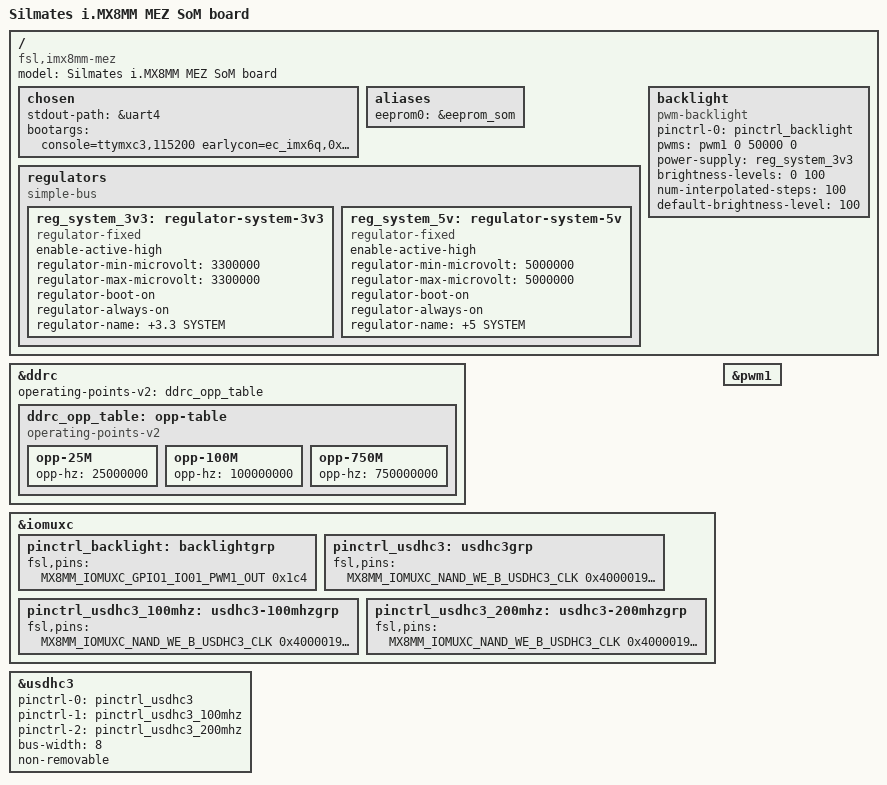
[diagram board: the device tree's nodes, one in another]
// SPDX-License-Identifier: (GPL-2.0+ OR MIT)
/*
 * Copyright 2019-2020 NXP
 */

/dts-v1/;

#include <dt-bindings/usb/pd.h>
#include "imx8mm-mez.dtsi"

/ {
	model = "Silmates i.MX8MM MEZ SoM board";
	compatible = "fsl,imx8mm-mez", "fsl,imx8mm";

	chosen {
		stdout-path = &uart4;
		bootargs = "console=ttymxc3,115200 earlycon=ec_imx6q,0x30a60000,115200";
	};

	aliases {
		eeprom0 = &eeprom_som;
	};

	regulators {
		compatible = "simple-bus";
		#address-cells = <1>;
		#size-cells = <0>;

		reg_system_3v3: regulator-system-3v3 {
			compatible = "regulator-fixed";
			enable-active-high;
			regulator-min-microvolt = <3300000>;
			regulator-max-microvolt = <3300000>;
			regulator-boot-on;
			regulator-always-on;
			regulator-name = "+3.3 SYSTEM";
		};

		reg_system_5v: regulator-system-5v {
			compatible = "regulator-fixed";
			enable-active-high;
			regulator-min-microvolt = <5000000>;
			regulator-max-microvolt = <5000000>;
			regulator-boot-on;
			regulator-always-on;
			regulator-name = "+5 SYSTEM";
		};
	};
	
	backlight: backlight {
		pinctrl-names = "default";
		pinctrl-0 = <&pinctrl_backlight>;
		compatible = "pwm-backlight";
		pwms = <&pwm1 0 50000 0>; /* period = 5000000 ns => f = 200 Hz */
		power-supply = <&reg_system_3v3>;
		brightness-levels = <0 100>;
		num-interpolated-steps = <100>;
		default-brightness-level = <100>;
		status = "okay";
	};
};

&ddrc {
	operating-points-v2 = <&ddrc_opp_table>;

	ddrc_opp_table: opp-table {
		compatible = "operating-points-v2";

		opp-25M {
			opp-hz = /bits/ 64 <25000000>;
		};

		opp-100M {
			opp-hz = /bits/ 64 <100000000>;
		};

		opp-750M {
			opp-hz = /bits/ 64 <750000000>;
		};
	};
};

&iomuxc {

	/* display backlight */
	pinctrl_backlight: backlightgrp {
		fsl,pins = <
			MX8MM_IOMUXC_GPIO1_IO01_PWM1_OUT		0x1c4
		>;
	};


	
// 	pinctrl_flexspi: flexspigrp {
// 		fsl,pins = <
// 			MX8MM_IOMUXC_NAND_ALE_QSPI_A_SCLK               0x1c2
// 			MX8MM_IOMUXC_NAND_CE0_B_QSPI_A_SS0_B            0x82
// 			MX8MM_IOMUXC_NAND_DATA00_QSPI_A_DATA0           0x82
// 			MX8MM_IOMUXC_NAND_DATA01_QSPI_A_DATA1           0x82
// 			MX8MM_IOMUXC_NAND_DATA02_QSPI_A_DATA2           0x82
// 			MX8MM_IOMUXC_NAND_DATA03_QSPI_A_DATA3           0x82
// 		>;
// 	};

	/* eMMC */
	pinctrl_usdhc3: usdhc3grp {
		fsl,pins = <
			MX8MM_IOMUXC_NAND_WE_B_USDHC3_CLK               0x40000190
			MX8MM_IOMUXC_NAND_WP_B_USDHC3_CMD               0x1d0
			MX8MM_IOMUXC_NAND_DATA04_USDHC3_DATA0           0x1d0
			MX8MM_IOMUXC_NAND_DATA05_USDHC3_DATA1           0x1d0
			MX8MM_IOMUXC_NAND_DATA06_USDHC3_DATA2           0x1d0
			MX8MM_IOMUXC_NAND_DATA06_USDHC3_DATA2           0x1d0
			MX8MM_IOMUXC_NAND_DATA07_USDHC3_DATA3           0x1d0
			MX8MM_IOMUXC_NAND_RE_B_USDHC3_DATA4             0x1d0
			MX8MM_IOMUXC_NAND_CE2_B_USDHC3_DATA5            0x1d0
			MX8MM_IOMUXC_NAND_CE3_B_USDHC3_DATA6            0x1d0
			MX8MM_IOMUXC_NAND_CLE_USDHC3_DATA7              0x1d0
			MX8MM_IOMUXC_NAND_CE1_B_USDHC3_STROBE           0x190
		>;
	};

	/* eMMC 100 MHz */
	pinctrl_usdhc3_100mhz: usdhc3-100mhzgrp {
		fsl,pins = <
			MX8MM_IOMUXC_NAND_WE_B_USDHC3_CLK               0x40000194
			MX8MM_IOMUXC_NAND_WP_B_USDHC3_CMD               0x1d4
			MX8MM_IOMUXC_NAND_DATA04_USDHC3_DATA0           0x1d4
			MX8MM_IOMUXC_NAND_DATA05_USDHC3_DATA1           0x1d4
			MX8MM_IOMUXC_NAND_DATA06_USDHC3_DATA2           0x1d4
			MX8MM_IOMUXC_NAND_DATA07_USDHC3_DATA3           0x1d4
			MX8MM_IOMUXC_NAND_RE_B_USDHC3_DATA4             0x1d4
			MX8MM_IOMUXC_NAND_CE2_B_USDHC3_DATA5            0x1d4
			MX8MM_IOMUXC_NAND_CE3_B_USDHC3_DATA6            0x1d4
			MX8MM_IOMUXC_NAND_CLE_USDHC3_DATA7              0x1d4
			MX8MM_IOMUXC_NAND_CE1_B_USDHC3_STROBE           0x194
		>;
	};

	/* eMMC 200 MHz */
	pinctrl_usdhc3_200mhz: usdhc3-200mhzgrp {
		fsl,pins = <
			MX8MM_IOMUXC_NAND_WE_B_USDHC3_CLK               0x40000196
			MX8MM_IOMUXC_NAND_WP_B_USDHC3_CMD               0x1d6
			MX8MM_IOMUXC_NAND_DATA04_USDHC3_DATA0           0x1d6
			MX8MM_IOMUXC_NAND_DATA05_USDHC3_DATA1           0x1d6
			MX8MM_IOMUXC_NAND_DATA06_USDHC3_DATA2           0x1d6
			MX8MM_IOMUXC_NAND_DATA07_USDHC3_DATA3           0x1d6
			MX8MM_IOMUXC_NAND_RE_B_USDHC3_DATA4             0x1d6
			MX8MM_IOMUXC_NAND_CE2_B_USDHC3_DATA5            0x1d6
			MX8MM_IOMUXC_NAND_CE3_B_USDHC3_DATA6            0x1d6
			MX8MM_IOMUXC_NAND_CLE_USDHC3_DATA7              0x1d6
			MX8MM_IOMUXC_NAND_CE1_B_USDHC3_STROBE           0x196
		>;
	};
};


// &flexspi {
// 	pinctrl-names = "default";
// 	pinctrl-0 = <&pinctrl_flexspi>;
// 	status = "okay";
// 
// 	flash@0 {
// 		reg = <0>;
// 		#address-cells = <1>;
// 		#size-cells = <1>;
// 		compatible = "jedec,spi-nor";
// 		spi-max-frequency = <80000000>;
// 		spi-tx-bus-width = <4>;
// 		spi-rx-bus-width = <4>;
// 	};
// };


&pwm1 {
	status = "okay";
};


/* eMMC */
&usdhc3 {
/*	assigned-clocks = <&clk IMX8MM_CLK_USDHC3_ROOT>;
	assigned-clock-rates = <400000000>;*/
	pinctrl-names = "default", "state_100mhz", "state_200mhz";
	pinctrl-0 = <&pinctrl_usdhc3>;
	pinctrl-1 = <&pinctrl_usdhc3_100mhz>;
	pinctrl-2 = <&pinctrl_usdhc3_200mhz>;
	bus-width = <8>;
	non-removable;
	status = "okay";
};

